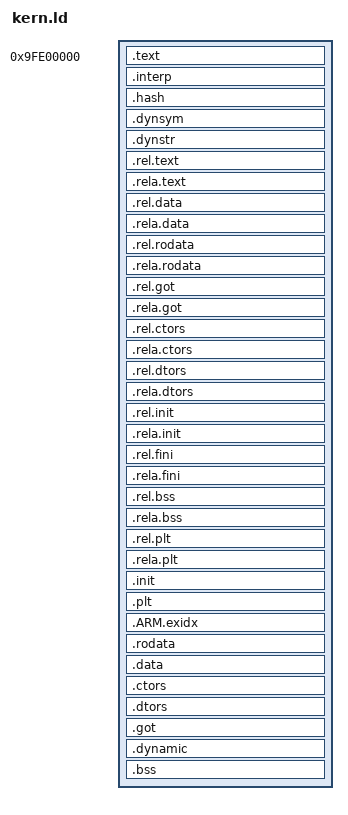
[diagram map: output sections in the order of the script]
/*
 * Copied from little-kernel. The original file (system-onesegment.ld)
 * doesn't have any copyright information, but Travis Geiselbrecht should
 * have credits for it at least.
 */
/*
 * Copyright (c) 2014, Linaro Limited
 * All rights reserved.
 *
 * Redistribution and use in source and binary forms, with or without
 * modification, are permitted provided that the following conditions are met:
 *
 * 1. Redistributions of source code must retain the above copyright notice,
 *    this list of conditions and the following disclaimer.
 *
 * 2. Redistributions in binary form must reproduce the above copyright
 *    notice, this list of conditions and the following disclaimer in the
 *    documentation and/or other materials provided with the distribution.
 *
 * THIS SOFTWARE IS PROVIDED BY THE COPYRIGHT HOLDERS AND CONTRIBUTORS "AS IS"
 * AND ANY EXPRESS OR IMPLIED WARRANTIES, INCLUDING, BUT NOT LIMITED TO, THE
 * IMPLIED WARRANTIES OF MERCHANTABILITY AND FITNESS FOR A PARTICULAR PURPOSE
 * ARE DISCLAIMED. IN NO EVENT SHALL THE COPYRIGHT HOLDER OR CONTRIBUTORS BE
 * LIABLE FOR ANY DIRECT, INDIRECT, INCIDENTAL, SPECIAL, EXEMPLARY, OR
 * CONSEQUENTIAL DAMAGES (INCLUDING, BUT NOT LIMITED TO, PROCUREMENT OF
 * SUBSTITUTE GOODS OR SERVICES; LOSS OF USE, DATA, OR PROFITS; OR BUSINESS
 * INTERRUPTION) HOWEVER CAUSED AND ON ANY THEORY OF LIABILITY, WHETHER IN
 * CONTRACT, STRICT LIABILITY, OR TORT (INCLUDING NEGLIGENCE OR OTHERWISE)
 * ARISING IN ANY WAY OUT OF THE USE OF THIS SOFTWARE, EVEN IF ADVISED OF THE
 * POSSIBILITY OF SUCH DAMAGE.
 */


OUTPUT_FORMAT("elf32-littlearm", "elf32-littlearm", "elf32-littlearm")
OUTPUT_ARCH(arm)

ENTRY(_start)
SECTIONS
{
	. = 0x9fe00000;

	/* text/read-only data */
	.text : {
		__text_start = .;
		KEEP(*(.text.boot.vectab1))
		KEEP(*(.text.boot.vectab2))
		KEEP(*(.text.boot))
		*(.text* .sram.text.glue_7* .gnu.linkonce.t.*)
		__text_end = .;
	}

	.interp : { *(.interp) }
	.hash : { *(.hash) }
	.dynsym : { *(.dynsym) }
	.dynstr : { *(.dynstr) }
	.rel.text : { *(.rel.text) *(.rel.gnu.linkonce.t*) }
	.rela.text : { *(.rela.text) *(.rela.gnu.linkonce.t*) }
	.rel.data : { *(.rel.data) *(.rel.gnu.linkonce.d*) }
	.rela.data : { *(.rela.data) *(.rela.gnu.linkonce.d*) }
	.rel.rodata : { *(.rel.rodata) *(.rel.gnu.linkonce.r*) }
	.rela.rodata : { *(.rela.rodata) *(.rela.gnu.linkonce.r*) }
	.rel.got : { *(.rel.got) }
	.rela.got : { *(.rela.got) }
	.rel.ctors : { *(.rel.ctors) }
	.rela.ctors : { *(.rela.ctors) }
	.rel.dtors : { *(.rel.dtors) }
	.rela.dtors : { *(.rela.dtors) }
	.rel.init : { *(.rel.init) }
	.rela.init : { *(.rela.init) }
	.rel.fini : { *(.rel.fini) }
	.rela.fini : { *(.rela.fini) }
	.rel.bss : { *(.rel.bss) }
	.rela.bss : { *(.rela.bss) }
	.rel.plt : { *(.rel.plt) }
	.rela.plt : { *(.rela.plt) }
	.init : { *(.init) } =0x9090
	.plt : { *(.plt) }

	/* .ARM.exidx is sorted, so has to go in its own output section.  */
	__exidx_start = .;
	.ARM.exidx : { *(.ARM.exidx* .gnu.linkonce.armexidx.*) }
	__exidx_end = .;

	.rodata : ALIGN(4) {
		__rodata_start = .;
		*(.rodata .rodata.* .gnu.linkonce.r.*)
		. = ALIGN(4);
		__rodata_end = .;
	}


	.data : ALIGN(4) {
		/* writable data  */
		__data_start_rom = .;
		/* in one segment binaries, the rom data address is on top of the ram data address */
		__data_start = .;
		*(.data .data.* .gnu.linkonce.d.*)
	}

	.ctors : ALIGN(4) {
		__ctor_list = .;
		*(.ctors)
		__ctor_end = .;
	}
	.dtors : ALIGN(4) {
		__dtor_list = .;
		*(.dtors)
		__dtor_end = .;
	}
	.got : { *(.got.plt) *(.got) }
	.dynamic : { *(.dynamic) }

	__data_end = .;

	/* unintialized data (in same segment as writable data) */
	.bss : ALIGN(4) {
		KEEP(*(.bss.prebss.*))
		. = ALIGN(4);
		__bss_start = .;
		*(.bss .bss.*)
		*(.gnu.linkonce.b.*)
		*(COMMON)
		. = ALIGN(4);
		__bss_end = .;
	}

	_end = .;

	. = 0x9fe00000 + 0x200000/*2MiB*/;
	_end_of_ram = .;

	/* Strip unnecessary stuff */
	/DISCARD/ : { *(.comment .note .eh_frame) }
}
